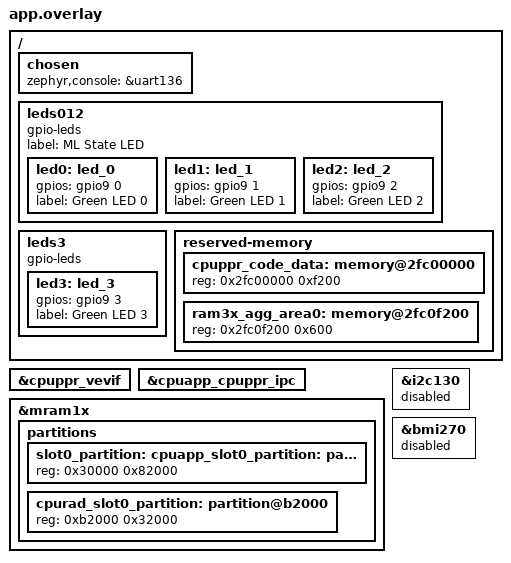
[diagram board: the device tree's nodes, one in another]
/*
 * Copyright (c) 2024 Nordic Semiconductor ASA
 *
 * SPDX-License-Identifier: LicenseRef-Nordic-5-Clause
 */

/ {
	chosen {
		zephyr,console = &uart136;
	};

	/* Redefine leds to fit CAF requirements. */
	/delete-node/ leds;

	leds012 {
		compatible = "gpio-leds";
		status = "okay";
		label = "ML State LED";

		led0: led_0 {
			gpios = <&gpio9 0 GPIO_ACTIVE_HIGH>;
			label = "Green LED 0";
		};

		led1: led_1 {
			gpios = <&gpio9 1 GPIO_ACTIVE_HIGH>;
			label = "Green LED 1";
		};

		led2: led_2 {
			gpios = <&gpio9 2 GPIO_ACTIVE_HIGH>;
			label = "Green LED 2";
		};
	};

	leds3 {
		compatible = "gpio-leds";

		led3: led_3 {
			gpios = <&gpio9 3 GPIO_ACTIVE_HIGH>;
			label = "Green LED 3";
		};
	};

	reserved-memory {
		cpuppr_code_data: memory@2fc00000 {
			reg = <0x2fc00000 0xf200>;
		};

		ram3x_agg_area0: memory@2fc0f200 {
			reg = <0x2fc0f200 0x600>;
		};
	};
};

&cpuppr_vevif {
	status = "okay";
};

ipc1: &cpuapp_cpuppr_ipc {
	status = "okay";
};

/delete-node/ &cpuapp_slot0_partition;
/delete-node/ &cpurad_slot0_partition;

&mram1x {
	partitions {
		slot0_partition: cpuapp_slot0_partition: partition@30000 {
			reg = <0x30000 0x82000>;
		};

		cpurad_slot0_partition: partition@b2000 {
			reg = <0xb2000 0x32000>;
		};
	};
};

/* Remove DTS nodes associated with the cpuflpr target as they refer to the
 * cpuflpr_code_partition label from the cpuapp_rx_partitions node. The label has
 * been removed in this file due to the modification of the cpuapp_rx_partitions
 * node. The cpuflpr_vpr and cpuapp_cpuflpr_ipc DTS nodes are removed to prevent
 * build failures.
 */
/delete-node/ &cpuflpr_vpr;
/delete-node/ &cpuapp_cpuflpr_ipc;

/* Disable unused sensors and peripherals. */
/delete-node/ &bme688;

&i2c130 {
	status = "disabled";
};

&bmi270 {
	status = "disabled";
};
